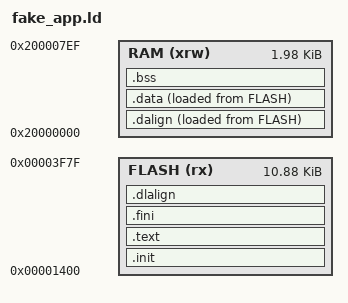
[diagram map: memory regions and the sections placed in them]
/* Linker for the fake APPLICATION used in the boot-chain test (DEV-31).
 *
 * Same witness harness as fake_stage1.c, but linked at the application base
 * (0x1400) so it can stand in for a real module app. Used to prove the full
 * chain: stage-0 -> real stage-1 -> application.
 *
 * Reuses stage-0's minimal start.S, so the no-.data / no-.bss constraint applies.
 */

ENTRY( InterruptVector )

MEMORY
{
	FLASH (rx) : ORIGIN = 0x00001400, LENGTH = 11136  /* app region to 0x3F7F  */
	RAM (xrw)  : ORIGIN = 0x20000000, LENGTH = 2032   /* 2 KB - 16 B (handoff) */
}

SECTIONS
{
	.init :
	{
		_sinit = .;
		. = ALIGN(4);
		KEEP(*(SORT_NONE(.init)))
		*(.text.vector_handler)
		. = ALIGN(4);
		_einit = .;
	} >FLASH AT>FLASH

	.text :
	{
		. = ALIGN(4);
		*(.text)
		*(.text.*)
		*(.rodata)
		*(.rodata*)
		*(.gnu.linkonce.t.*)
		. = ALIGN(4);
	} >FLASH AT>FLASH

	.fini :
	{
		KEEP(*(SORT_NONE(.fini)))
		. = ALIGN(4);
	} >FLASH AT>FLASH

	PROVIDE( _etext = . );

	.dalign :
	{
		. = ALIGN(4);
		PROVIDE(_data_vma = .);
	} >RAM AT>FLASH

	.dlalign :
	{
		. = ALIGN(4);
		PROVIDE(_data_lma = .);
	} >FLASH AT>FLASH

	.data :
	{
		. = ALIGN(4);
		*(.data.vector_handler)
		*(.gnu.linkonce.r.*)
		*(.data .data.*)
		*(.gnu.linkonce.d.*)
		. = ALIGN(8);
		PROVIDE( __global_pointer$ = . + 0x800 );
		*(.sdata .sdata.*)
		*(.sdata2*)
		*(.gnu.linkonce.s.*)
		. = ALIGN(8);
		*(.srodata.cst16)
		*(.srodata.cst8)
		*(.srodata.cst4)
		*(.srodata.cst2)
		*(.srodata .srodata.*)
		. = ALIGN(4);
		PROVIDE( _edata = .);
	} >RAM AT>FLASH

	.bss :
	{
		. = ALIGN(4);
		PROVIDE( _sbss = .);
		*(.sbss*)
		*(.gnu.linkonce.sb.*)
		*(.bss*)
		*(.gnu.linkonce.b.*)
		*(COMMON*)
		. = ALIGN(4);
		PROVIDE( _ebss = .);
	} >RAM

	PROVIDE( _end = _ebss);
	PROVIDE( end = . );

	PROVIDE( _eusrstack = ORIGIN(RAM) + LENGTH(RAM));   /* = 0x200007F0 */
}

ASSERT( SIZEOF(.data) == 0, "fake app must have no .data — start.S does not copy it" )
ASSERT( SIZEOF(.bss)  == 0, "fake app must have no .bss — start.S does not zero it" )
ASSERT( ADDR(.init) == 0x00001400, "fake app must start at the application base (0x1400, layout 2)" )
